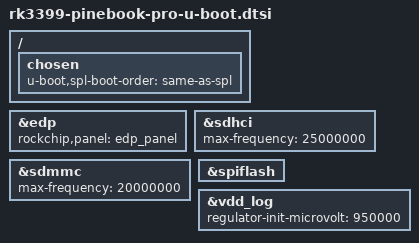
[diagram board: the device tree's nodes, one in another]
// SPDX-License-Identifier: GPL-2.0+
/*
 * Copyright (C) 2019 Peter Robinson <pbrobinson at gmail.com>
 */

#include "rk3399-u-boot.dtsi"
#include "rk3399-sdram-lpddr4-100.dtsi"

/ {
	chosen {
		u-boot,spl-boot-order = "same-as-spl", &sdhci, &spiflash, &sdmmc;
	};
};

&edp {
	rockchip,panel = <&edp_panel>;
};

&sdhci {
	max-frequency = <25000000>;
	bootph-all;
};

&sdmmc {
	max-frequency = <20000000>;
	bootph-all;
};

&spiflash {
	bootph-all;
};

&vdd_log {
	regulator-init-microvolt = <950000>;
};
